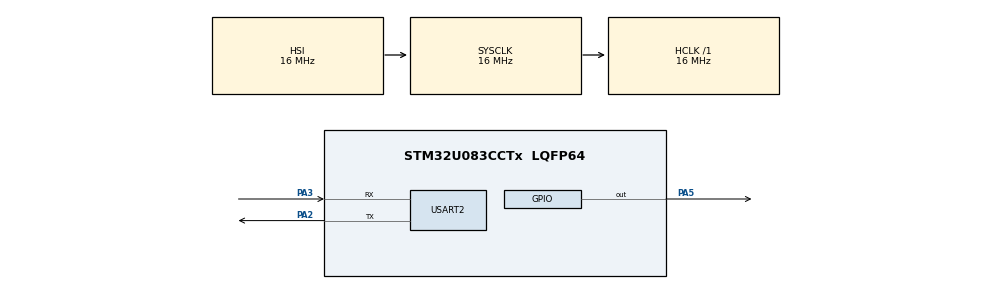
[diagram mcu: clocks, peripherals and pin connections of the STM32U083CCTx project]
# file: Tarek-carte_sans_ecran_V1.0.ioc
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Mcu.Family=STM32U0
Mcu.Name=STM32U083CCTx
Mcu.Package=LQFP64
NVIC.PriorityGroup=NVIC_PRIORITYGROUP_2
NVIC.USART2_LPUART2_IRQn=true\:0\:0\:false\:false\:true\:true\:true\:true
PA2.Mode=Asynchronous
PA2.Signal=USART2_TX
PA3.Mode=Asynchronous
PA3.Signal=USART2_RX
PA5.Signal=GPIO_Output
ProjectManager.HeapSize=0x200
ProjectManager.StackSize=0x400
ProjectManager.TargetToolchain=STM32CubeIDE
RCC.AHBFreq_Value=16000000
RCC.CortexFreq_Value=16000000
RCC.HCLKFreq_Value=16000000
RCC.HSE_VALUE=4000000
RCC.HSI48_VALUE=48000000
RCC.HSI_VALUE=16000000
RCC.LSE_VALUE=32768
RCC.MSI_VALUE=4000000
RCC.SYSCLKFreq_VALUE=16000000
RCC.VCOOutputFreq_Value=64000000
USART2.VirtualMode-Asynchronous=VM_ASYNC
VP_PWR_VS_SECSignals.Mode=Security/Privilege
board=custom

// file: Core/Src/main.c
/* USER CODE BEGIN Header */
/**
  ******************************************************************************
  * @file           : main.c
  * @brief          : Main program body
  ******************************************************************************
  * @attention
  *
  * Copyright (c) 2026 STMicroelectronics.
  * All rights reserved.
  *
  * This software is licensed under terms that can be found in the LICENSE file
  * in the root directory of this software component.
  * If no LICENSE file comes with this software, it is provided AS-IS.
  *
  ******************************************************************************
  */
/* USER CODE END Header */
#include "main.h"

/* USER CODE BEGIN Includes */
#include <string.h>
/* USER CODE END Includes */

UART_HandleTypeDef huart2;

/* USER CODE BEGIN PV */
uint8_t rx_byte[1];       // La boîte pour recevoir 1 seule lettre à la fois
char rx_buffer[20];       // Le carnet (buffer) pour écrire le mot en entier (max 20 lettres)
uint8_t rx_index = 0;     // Le stylo (l'index) qui retient à quelle case on est rendu
// NOUVELLE VARIABLE : Chronomètre du dernier ordre
uint32_t temps_dernier_ordre = 0;
/* USER CODE END PV */

void SystemClock_Config(void);
static void MX_GPIO_Init(void);
static void MX_USART2_UART_Init(void);

int main(void)
{

  /* MCU Configuration--------------------------------------------------------*/

  /* Reset of all peripherals, Initializes the Flash interface and the Systick. */
  HAL_Init();

  /* Configure the system clock */
  SystemClock_Config();

  /* Initialize all configured peripherals */
  MX_GPIO_Init();
  MX_USART2_UART_Init();
  /* USER CODE BEGIN 2 */

  // ---> NOUVEAU : On allume la LED verte (Simulation de l'écran ALLUMÉ)
  HAL_GPIO_WritePin(GPIOA, GPIO_PIN_5, GPIO_PIN_SET);

  // 1. Envoi du message de démarrage UNE SEULE FOIS
  uint8_t message[] = "Test de la carte OK ! En attente d'ordres...\r\n";
  HAL_UART_Transmit(&huart2, message, sizeof(message)-1, 1000);

  // 2. Armement de l'interruption pour écouter le premier caractère
  HAL_UART_Receive_IT(&huart2, rx_byte, 1);
  /* USER CODE END 2 */

  /* Infinite loop */
  while (1)
  {

    /* USER CODE BEGIN 3 */
	  // 1. On calcule combien de temps s'est écoulé depuis le  dernier ordre
	        uint32_t temps_actuel = HAL_GetTick();
	        uint32_t temps_ecoule = temps_actuel - temps_dernier_ordre;

	        // 2. Si ça fait plus de 10 000 ms (10 secondes)
	        if (temps_ecoule > 10000)
	        {
	            // On prépare un message pour avertir le PC
	            uint8_t msg_veille[] = "Zzz... 10s d'inactivite, je passe en VEILLE !\r\n";
	            HAL_UART_Transmit(&huart2, msg_veille, sizeof(msg_veille)-1, 10);

	            // ---> NOUVEAU : On éteint la LED verte (Simulation de l'écran ÉTEINT)
	            HAL_GPIO_WritePin(GPIOA, GPIO_PIN_5, GPIO_PIN_RESET);

	            // NOTE POUR PLUS TARD : C'est ici que tu mettras la VRAIE fonction
	            // pour couper l'alimentation de l'écran TFT et endormir le STM32.

	            // Pour éviter que le message s'affiche en boucle toutes les millisecondes,
	            // on triche un peu pour le test : on remet le chrono à zéro.
	            temps_dernier_ordre = HAL_GetTick();
	        }
  }
  /* USER CODE END 3 */
}

void SystemClock_Config(void)
{
  RCC_OscInitTypeDef RCC_OscInitStruct = {0};
  RCC_ClkInitTypeDef RCC_ClkInitStruct = {0};

  /** Configure the main internal regulator output voltage
  */
  HAL_PWREx_ControlVoltageScaling(PWR_REGULATOR_VOLTAGE_SCALE2);

  /** Initializes the RCC Oscillators according to the specified parameters
  * in the RCC_OscInitTypeDef structure.
  */
  RCC_OscInitStruct.OscillatorType = RCC_OSCILLATORTYPE_HSI;
  RCC_OscInitStruct.HSIState = RCC_HSI_ON;
  RCC_OscInitStruct.HSICalibrationValue = RCC_HSICALIBRATION_DEFAULT;
  RCC_OscInitStruct.PLL.PLLState = RCC_PLL_NONE;
  if (HAL_RCC_OscConfig(&RCC_OscInitStruct) != HAL_OK)
  {
    Error_Handler();
  }

  /** Initializes the CPU, AHB and APB buses clocks
  */
  RCC_ClkInitStruct.ClockType = RCC_CLOCKTYPE_HCLK|RCC_CLOCKTYPE_SYSCLK
                              |RCC_CLOCKTYPE_PCLK1;
  RCC_ClkInitStruct.SYSCLKSource = RCC_SYSCLKSOURCE_HSI;
  RCC_ClkInitStruct.AHBCLKDivider = RCC_SYSCLK_DIV1;
  RCC_ClkInitStruct.APB1CLKDivider = RCC_HCLK_DIV1;

  if (HAL_RCC_ClockConfig(&RCC_ClkInitStruct, FLASH_LATENCY_1) != HAL_OK)
  {
    Error_Handler();
  }
}

static void MX_USART2_UART_Init(void)
{

  huart2.Instance = USART2;
  huart2.Init.BaudRate = 115200;
  huart2.Init.WordLength = UART_WORDLENGTH_8B;
  huart2.Init.StopBits = UART_STOPBITS_1;
  huart2.Init.Parity = UART_PARITY_NONE;
  huart2.Init.Mode = UART_MODE_TX_RX;
  huart2.Init.HwFlowCtl = UART_HWCONTROL_NONE;
  huart2.Init.OverSampling = UART_OVERSAMPLING_16;
  huart2.Init.OneBitSampling = UART_ONE_BIT_SAMPLE_DISABLE;
  huart2.Init.ClockPrescaler = UART_PRESCALER_DIV1;
  huart2.AdvancedInit.AdvFeatureInit = UART_ADVFEATURE_NO_INIT;
  if (HAL_UART_Init(&huart2) != HAL_OK)
  {
    Error_Handler();
  }
  if (HAL_UARTEx_SetTxFifoThreshold(&huart2, UART_TXFIFO_THRESHOLD_1_8) != HAL_OK)
  {
    Error_Handler();
  }
  if (HAL_UARTEx_SetRxFifoThreshold(&huart2, UART_RXFIFO_THRESHOLD_1_8) != HAL_OK)
  {
    Error_Handler();
  }
  if (HAL_UARTEx_DisableFifoMode(&huart2) != HAL_OK)
  {
    Error_Handler();
  }

}

static void MX_GPIO_Init(void)
{
  GPIO_InitTypeDef GPIO_InitStruct = {0};

  /* GPIO Ports Clock Enable */
  __HAL_RCC_GPIOA_CLK_ENABLE();

  /*Configure GPIO pin Output Level */
  HAL_GPIO_WritePin(GPIOA, GPIO_PIN_5, GPIO_PIN_RESET);

  /*Configure GPIO pin : PA5 */
  GPIO_InitStruct.Pin = GPIO_PIN_5;
  GPIO_InitStruct.Mode = GPIO_MODE_OUTPUT_PP;
  GPIO_InitStruct.Pull = GPIO_NOPULL;
  GPIO_InitStruct.Speed = GPIO_SPEED_FREQ_LOW;
  HAL_GPIO_Init(GPIOA, &GPIO_InitStruct);

}

/* USER CODE BEGIN 4 */
void HAL_UART_RxCpltCallback(UART_HandleTypeDef *huart)
{
    if (huart->Instance == USART2)
    {
        // 1. Est-ce que la lettre qu'on vient de recevoir est un "Retour à la ligne" ?
        // (Sur Hercules, quand tu envoies un mot, ça ajoute souvent \r ou \n à la fin)
    	if (rx_byte[0] == '\r' || rx_byte[0] == '\n')
    	        {
    		// C'est la fin du mot. On ferme le mot proprement avec '\0'
    		rx_buffer[rx_index] = '\0';

    	    // ---> IMPORTANT : On remet à zéro le chrono de veille et on rallume l'écran (LED)
    		temps_dernier_ordre = HAL_GetTick();
    		HAL_GPIO_WritePin(GPIOA, GPIO_PIN_5, GPIO_PIN_SET);
    		// <---

    		// ====================================================//.
    		// NOUVELLE GESTION DES 4 TOUCHES (MENU, UP, DOWN, OK) //
    		// ====================================================//
    		if (strcmp(rx_buffer, "MENU") == 0)
    			{
    			uint8_t msg_menu[] = "--> Action : Affichage MENU PRINCIPAL\r\n";
    			HAL_UART_Transmit(&huart2, msg_menu, sizeof(msg_menu)-1, 10);
    			}
    		else if (strcmp(rx_buffer, "UP") == 0)
    	        {
    			uint8_t msg_up[] = "--> Action : Navigation HAUT\r\n";
    	        HAL_UART_Transmit(&huart2, msg_up, sizeof(msg_up)-1, 10);
    	        }
    	            else if (strcmp(rx_buffer, "DOWN") == 0)
    	            {
    	                uint8_t msg_down[] = "--> Action : Navigation BAS\r\n";
    	                HAL_UART_Transmit(&huart2, msg_down, sizeof(msg_down)-1, 10);
    	            }
    	            else if (strcmp(rx_buffer, "OK") == 0)
    	            {
    	                uint8_t msg_ok[] = "--> Action : VALIDATION (OK)\r\n";
    	                HAL_UART_Transmit(&huart2, msg_ok, sizeof(msg_ok)-1, 10);
    	            }
    	            // Si on a tapé un mot inconnu (et que ce n'est pas juste un mot vide)
    	            else if (rx_index > 0)
    	            {
    	                uint8_t msg_err[] = "--> Erreur : Touche non reconnue...\r\n";
    	                HAL_UART_Transmit(&huart2, msg_err, sizeof(msg_err)-1, 10);
    	            }
    	            // ==========================================

    	            // On a fini de lire, on remet le "stylo" à zéro
    	            rx_index = 0;
        }
        else
        {
            // NON, ce n'est pas la fin du mot. C'est une lettre normale (ex: 'O' ou 'N')
            // On l'ajoute dans notre carnet, tant qu'il y a de la place
            if (rx_index < 19)
            {
                rx_buffer[rx_index] = rx_byte[0]; // On écrit la lettre
                rx_index++;                       // On avance le stylo d'une case
            }
        }

        // 6. On réarme l'interruption pour écouter la PROCHAINE lettre
        HAL_UART_Receive_IT(&huart2, rx_byte, 1);
    }
}
/* USER CODE END 4 */

void Error_Handler(void)
{
  __disable_irq();
  while (1)
  {
  }
}
